# YTM32B1ME0 register map
Vendor: YTMicro; File version: 1.6
CPU: CM33 r0p4, little endian, MPU, FPU, 2 interrupt priority bits
Registers are 32-bit, read-write, reset 0x0 unless marked. A register's access mark holds for its fields unless they carry their own. Offsets are from the block's base; [hi:lo] are bit positions; {n}, {i} and the like mark numbered series.

## WKU — Wake-up Unit
Base 0x40062000; register names take the prefix WKU_
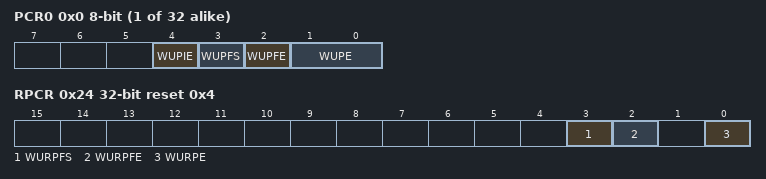
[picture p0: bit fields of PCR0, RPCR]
{0x0+i} PCR{i} 8-bit (i=0..31) — This register includes the field to enable and select the edge detect type for the external wake-up input pins.
  [4] WUPIE — Interrupt should always be enabled when pin selected as wake-up source
    0=wake-up pin interrupt is disabled; 1=wake-up pin interrupt is enabled
  [3] WUPFS — Select wake-up pin filter clock source.
    0=SIRC clock is selected as wake-up in filter clock source; 1=SXOSC clock is selected as wake-up in filter clock source
  [2] WUPFE — Enables the digital filter for the external pin detect.
    0=Filter disabled; 1=Filter enabled
  [1:0] WUPE — Enables and configures the edge detection for the wake-up pin.
    0=External input pin disabled as wake-up input; 1=External input pin enabled with rising edge detection; 2=External input pin enabled with falling edge detection; 3=External input pin enabled with rising or falling edge detection
0x20 PFR0 — The PFR register contains the wake-up flags indicating which wake-up source caused the MCU to exit Powerdown mode. The external wake-up flags are read-only and clearing a flag is accomplished by a write of a 1 to the corresponding WUFn bit. The wake-up flag (WUFn), if set, will remain set if the associated PCRn[WUPE] bit is cleared.
  [31:0] WUF — Indicates that an enabled external wake-up pin was a source of exiting a Powerdown mode. Write 1 to clear this bit. 0b - WKU_PINn input was not a wake-up source 1b - WKU_PINn input was a wake-up source
0x24 RPCR reset 0x4 — This register controls the reset pin filter functions.
  [3] WURPFS — Select Reset pin filter clock source.
    0=SIRC clock is selected as Reset pin filter clock source; 1=SXOSC clock is selected as Reset pin filter clock source
  [2] WURPFE — Enable bit of Reset pin filter, this bit should be set if filter need to be used.
    0=Disable reset pin filter; 1=Enable reset pin filter
  [0] WURPE — Enable Reset pin as a wake-up source input.
    0=Reset pin not used as wake-up source; 1=Reset pin used as wake-up source
0x28 MER — This register contains the bits to enable an internal module interrupt as a wake-up source.
  [3:0] WUME
    1=RTC_IRQ; 2=RTC_Seconds_IRQ; 4=lpTMR0_IRQ; 8=ACMP0_IRQ

## TMR0
Base 0x40054000; register names take the prefix TMR0_
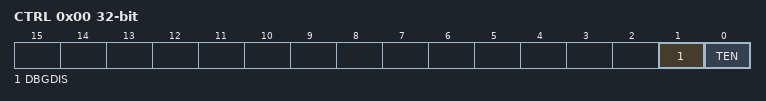
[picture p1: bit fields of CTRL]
0x00 CTRL
  [1] DBGDIS — Stops the timer when the chip enters debug mode.
    0=The timer runs in debug mode; 1=The timer stops in debug mode
  [0] TEN — Enable the timer.
    0=The timer is disabled; 1=The timer is enabled
0x04 PRS
  [7:0] PRS — Selects the module clock divide value for the prescaler (1–256). The module clock is divided by (PRS + 1)
0x08 CNT — Holds the timer count value.
  [31:0] CNT — The time base for all compare channels. When enabled, the timer count increments at the rate of the module clock divided by the prescale value. Writing operation to this register will load writing value to it immediately.
{0x10+0x10*i} CH{i}_CTRL (i=0..3)
  [0] CHEN
    0=Channel is disabled; 1=Channel is enabled
{0x14+0x10*i} CH{i}_INT (i=0..3)
  [0] CHIF — Indicates the channel interrupt is asserted due to a match on the channel. Write 1 to clear it.
    0=Channel interrupt is not asserted; 1=Channel interrupt is asserted
{0x18+0x10*i} CH{i}_CMP (i=0..3)
  [31:0] CHCMP — If the channel is enabled (CH_CTRL[CHEN]), when the timer count (CNT) matches this value, TMR asserts the channel interrupt and sets the channel interrupt flag (CH_INT[CHIF]).

## pTMR0 — Periodic timer
Base 0x4005A000; register names take the prefix pTMR0_
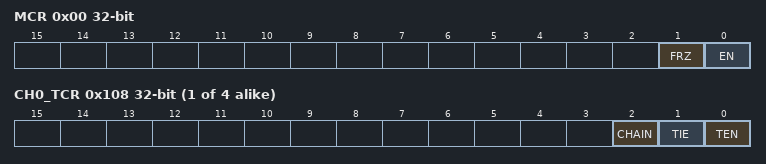
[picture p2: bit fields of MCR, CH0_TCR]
0x00 MCR
  [1] FRZ — Allows the timers to be stopped when the device enters debug mode.
    0=pTMR continues to run in debug mode; 1=pTMR stops in debug mode
  [0] EN — Enable pTMR module
    0=pTMR is disabled; 1=pTMR is enabled
{0x100+0x10*i} CH{i}_TSV (i=0..3) — Timer Start Value Register
  [31:0] STVAL — This register set the timer start value. The timer will count down until it reaches 0, then it will generate an interrupt and loads the value again. Writing a new value to this register will not restart the timer, instead the value will be loaded once the timer expires. To abort the current cycle and start a timer period with the new value, the timer must be disabled and enabled again.
{0x104+0x10*i} CH{i}_TCV (i=0..3) — Timer Current Value Register
  [31:0] CVAL — This register stands for current timer value when user read this register. The value of this register will be frozen in debug mode if MCR[FRZ] is set.
{0x108+0x10*i} CH{i}_TCR (i=0..3) — Timer Control Register
  [2] CHAIN — When setting this bit, it will link multi-channel in sequence to combine a new bits counter, it just links the front channel.
    0=Chaining is disabled, channel timer runs independently; 1=Chaining is enabled
  [1] TIE — Enable interrupt when setting this bit
    0=Disable timer interrupt of corresponding channel; 1=Enable timer interrupt of corresponding channel
  [0] TEN — Enable the timer of corresponding channel
    0=Disable the timer of corresponding channel; 1=Enable the timer of corresponding channel
{0x10C+0x10*i} CH{i}_TFR (i=0..3) — Timer Flag Register
  [0] TIF — Hardware will set this bit as 1 when timer interrupt is enabled, and writing logic 1 to this bit will clear this bit as 0.
    0=Timeout did not occur; 1=Timeout occurred
